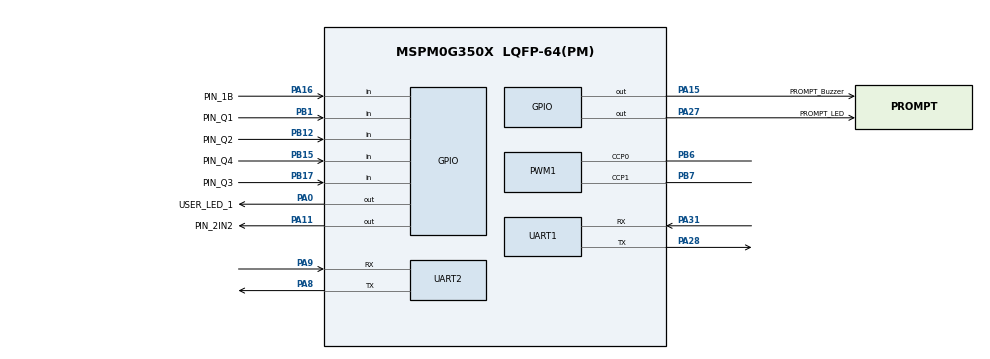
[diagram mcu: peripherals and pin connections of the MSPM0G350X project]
/**
 * @cliArgs --device "MSPM0G350X" --package "LQFP-64(PM)" --part "Default" --product "mspm0_sdk@2.01.00.03"
 * @versions {"tool":"1.20.0+3587"}
 */

/**
 * Import the modules used in this configuration.
 */
const GPIO   = scripting.addModule("/ti/driverlib/GPIO", {}, false);
const GPIO1  = GPIO.addInstance();
const GPIO2  = GPIO.addInstance();
const GPIO3  = GPIO.addInstance();
const GPIO4  = GPIO.addInstance();
const GPIO5  = GPIO.addInstance();
const GPIO6  = GPIO.addInstance();
const PWM    = scripting.addModule("/ti/driverlib/PWM", {}, false);
const PWM1   = PWM.addInstance();
const TIMER  = scripting.addModule("/ti/driverlib/TIMER", {}, false);
const TIMER1 = TIMER.addInstance();
const TIMER2 = TIMER.addInstance();
const UART   = scripting.addModule("/ti/driverlib/UART", {}, false);
const UART1  = UART.addInstance();
const UART2  = UART.addInstance();

/**
 * Write custom configuration values to the imported modules.
 */
GPIO1.$name                              = "GPIO_Flag";
GPIO1.associatedPins.create(4);
GPIO1.associatedPins[0].$name            = "USER_LED_1";
GPIO1.associatedPins[0].assignedPort     = "PORTA";
GPIO1.associatedPins[0].initialValue     = "SET";
GPIO1.associatedPins[0].assignedPin      = "0";
GPIO1.associatedPins[0].pin.$assign      = "PA0";
GPIO1.associatedPins[1].assignedPort     = "PORTA";
GPIO1.associatedPins[1].assignedPin      = "15";
GPIO1.associatedPins[1].initialValue     = "SET";
GPIO1.associatedPins[1].$name            = "PROMPT_Buzzer";
GPIO1.associatedPins[1].internalResistor = "PULL_UP";
GPIO1.associatedPins[1].pin.$assign      = "PA15";
GPIO1.associatedPins[2].$name            = "PROMPT_LED";
GPIO1.associatedPins[2].assignedPort     = "PORTA";
GPIO1.associatedPins[2].assignedPin      = "27";
GPIO1.associatedPins[2].internalResistor = "PULL_DOWN";
GPIO1.associatedPins[2].pin.$assign      = "PA27";
GPIO1.associatedPins[3].direction        = "INPUT";
GPIO1.associatedPins[3].$name            = "PIN_ResetYaw";
GPIO1.associatedPins[3].internalResistor = "PULL_UP";
GPIO1.associatedPins[3].assignedPort     = "PORTB";
GPIO1.associatedPins[3].assignedPin      = "21";

const Board           = scripting.addModule("/ti/driverlib/Board", {}, false);
Board.configureUnused = true;

GPIO2.$name                          = "GPIO_OLED";
GPIO2.associatedPins.create(2);
GPIO2.associatedPins[0].$name        = "PIN_SCL";
GPIO2.associatedPins[0].assignedPort = "PORTA";
GPIO2.associatedPins[0].assignedPin  = "13";
GPIO2.associatedPins[1].$name        = "PIN_SDA";
GPIO2.associatedPins[1].assignedPin  = "12";
GPIO2.associatedPins[1].assignedPort = "PORTA";

GPIO3.$name                          = "GPIO_Motor";
GPIO3.associatedPins.create(4);
GPIO3.associatedPins[0].$name        = "PIN_1IN1";
GPIO3.associatedPins[0].assignedPort = "PORTB";
GPIO3.associatedPins[0].assignedPin  = "8";
GPIO3.associatedPins[1].$name        = "PIN_1IN2";
GPIO3.associatedPins[1].assignedPort = "PORTB";
GPIO3.associatedPins[1].assignedPin  = "13";
GPIO3.associatedPins[2].$name        = "PIN_2IN1";
GPIO3.associatedPins[2].assignedPort = "PORTB";
GPIO3.associatedPins[2].assignedPin  = "0";
GPIO3.associatedPins[3].$name        = "PIN_2IN2";
GPIO3.associatedPins[3].pin.$assign  = "PA11";

GPIO4.$name                          = "GPIO_Encoder";
GPIO4.associatedPins.create(2);
GPIO4.associatedPins[0].$name        = "PIN_1A";
GPIO4.associatedPins[0].direction    = "INPUT";
GPIO4.associatedPins[0].interruptEn  = true;
GPIO4.associatedPins[0].polarity     = "RISE";
GPIO4.associatedPins[0].assignedPort = "PORTA";
GPIO4.associatedPins[0].assignedPin  = "17";
GPIO4.associatedPins[1].direction    = "INPUT";
GPIO4.associatedPins[1].interruptEn  = true;
GPIO4.associatedPins[1].polarity     = "RISE";
GPIO4.associatedPins[1].$name        = "PIN_1B";
GPIO4.associatedPins[1].pin.$assign  = "PA16";

GPIO5.$name                          = "GPIO_SensorTracking";
GPIO5.associatedPins.create(7);
GPIO5.associatedPins[0].$name        = "PIN_1";
GPIO5.associatedPins[0].assignedPort = "PORTA";
GPIO5.associatedPins[0].direction    = "INPUT";
GPIO5.associatedPins[0].assignedPin  = "25";
GPIO5.associatedPins[1].$name        = "PIN_2";
GPIO5.associatedPins[1].direction    = "INPUT";
GPIO5.associatedPins[1].assignedPin  = "24";
GPIO5.associatedPins[1].assignedPort = "PORTB";
GPIO5.associatedPins[2].$name        = "PIN_3";
GPIO5.associatedPins[2].assignedPort = "PORTB";
GPIO5.associatedPins[2].direction    = "INPUT";
GPIO5.associatedPins[2].assignedPin  = "9";
GPIO5.associatedPins[3].$name        = "PIN_4";
GPIO5.associatedPins[3].assignedPort = "PORTB";
GPIO5.associatedPins[3].assignedPin  = "19";
GPIO5.associatedPins[3].direction    = "INPUT";
GPIO5.associatedPins[4].$name        = "PIN_5";
GPIO5.associatedPins[4].assignedPort = "PORTA";
GPIO5.associatedPins[4].assignedPin  = "22";
GPIO5.associatedPins[4].direction    = "INPUT";
GPIO5.associatedPins[5].$name        = "PIN_6";
GPIO5.associatedPins[5].assignedPort = "PORTB";
GPIO5.associatedPins[5].assignedPin  = "18";
GPIO5.associatedPins[5].direction    = "INPUT";
GPIO5.associatedPins[6].$name        = "PIN_7";
GPIO5.associatedPins[6].assignedPort = "PORTA";
GPIO5.associatedPins[6].assignedPin  = "18";
GPIO5.associatedPins[6].direction    = "INPUT";

GPIO6.$name                              = "GPIO_Questions";
GPIO6.associatedPins.create(4);
GPIO6.associatedPins[0].$name            = "PIN_Q1";
GPIO6.associatedPins[0].direction        = "INPUT";
GPIO6.associatedPins[0].internalResistor = "PULL_UP";
GPIO6.associatedPins[0].polarity         = "RISE";
GPIO6.associatedPins[0].inputFilter      = "8_CYCLES";
GPIO6.associatedPins[0].interruptEn      = true;
GPIO6.associatedPins[0].pin.$assign      = "PB1";
GPIO6.associatedPins[1].$name            = "PIN_Q2";
GPIO6.associatedPins[1].direction        = "INPUT";
GPIO6.associatedPins[1].internalResistor = "PULL_UP";
GPIO6.associatedPins[1].polarity         = "RISE";
GPIO6.associatedPins[1].inputFilter      = "8_CYCLES";
GPIO6.associatedPins[1].interruptEn      = true;
GPIO6.associatedPins[1].pin.$assign      = "PB12";
GPIO6.associatedPins[2].$name            = "PIN_Q3";
GPIO6.associatedPins[2].direction        = "INPUT";
GPIO6.associatedPins[2].internalResistor = "PULL_UP";
GPIO6.associatedPins[2].polarity         = "RISE";
GPIO6.associatedPins[2].inputFilter      = "8_CYCLES";
GPIO6.associatedPins[2].interruptEn      = true;
GPIO6.associatedPins[2].pin.$assign      = "PB17";
GPIO6.associatedPins[3].$name            = "PIN_Q4";
GPIO6.associatedPins[3].direction        = "INPUT";
GPIO6.associatedPins[3].internalResistor = "PULL_UP";
GPIO6.associatedPins[3].polarity         = "RISE";
GPIO6.associatedPins[3].inputFilter      = "8_CYCLES";
GPIO6.associatedPins[3].interruptEn      = true;
GPIO6.associatedPins[3].pin.$assign      = "PB15";

PWM1.$name                              = "PWM_Motor";
PWM1.clockDivider                       = 2;
PWM1.clockPrescale                      = 16;
PWM1.pwmMode                            = "EDGE_ALIGN_UP";
PWM1.peripheral.$assign                 = "TIMG6";
PWM1.peripheral.ccp0Pin.$assign         = "PB6";
PWM1.peripheral.ccp1Pin.$assign         = "PB7";
PWM1.PWM_CHANNEL_0.$name                = "ti_driverlib_pwm_PWMTimerCC0";
PWM1.PWM_CHANNEL_0.dutyCycle            = 75;
PWM1.PWM_CHANNEL_1.$name                = "ti_driverlib_pwm_PWMTimerCC1";
PWM1.PWM_CHANNEL_1.dutyCycle            = 75;
PWM1.ccp0PinConfig.direction            = scripting.forceWrite("OUTPUT");
PWM1.ccp0PinConfig.hideOutputInversion  = scripting.forceWrite(false);
PWM1.ccp0PinConfig.onlyInternalResistor = scripting.forceWrite(false);
PWM1.ccp0PinConfig.passedPeripheralType = scripting.forceWrite("Digital");
PWM1.ccp0PinConfig.$name                = "ti_driverlib_gpio_GPIOPinGeneric4";
PWM1.ccp1PinConfig.direction            = scripting.forceWrite("OUTPUT");
PWM1.ccp1PinConfig.hideOutputInversion  = scripting.forceWrite(false);
PWM1.ccp1PinConfig.onlyInternalResistor = scripting.forceWrite(false);
PWM1.ccp1PinConfig.passedPeripheralType = scripting.forceWrite("Digital");
PWM1.ccp1PinConfig.$name                = "ti_driverlib_gpio_GPIOPinGeneric5";

const SYSCTL                 = scripting.addModule("/ti/driverlib/SYSCTL", {}, false);
SYSCTL.powerPolicy           = "STANDBY0";
SYSCTL.forceDefaultClkConfig = true;
SYSCTL.clockTreeEn           = true;

TIMER1.timerClkDiv        = 4;
TIMER1.timerClkPrescale   = 128;
TIMER1.timerMode          = "PERIODIC";
TIMER1.interrupts         = ["ZERO"];
TIMER1.$name              = "TIMER_computePID";
TIMER1.timerPeriod        = "200 ms";
TIMER1.peripheral.$assign = "TIMA0";

TIMER2.timerClkDiv        = 4;
TIMER2.interrupts         = ["ZERO"];
TIMER2.timerMode          = "PERIODIC";
TIMER2.$name              = "TIMER_Debug";
TIMER2.timerClkPrescale   = 128;
TIMER2.timerPeriod        = "600 ms";
TIMER2.peripheral.$assign = "TIMA1";

UART1.$name                    = "UART_0";
UART1.rxFifoThreshold          = "DL_UART_RX_FIFO_LEVEL_ONE_ENTRY";
UART1.enableDMARX              = false;
UART1.enableDMATX              = false;
UART1.enabledInterrupts        = ["RX"];
UART1.targetBaudRate           = 115200;
UART1.peripheral.$assign       = "UART0";
UART1.peripheral.rxPin.$assign = "PA31";
UART1.peripheral.txPin.$assign = "PA28";
UART1.txPinConfig.$name        = "ti_driverlib_gpio_GPIOPinGeneric0";
UART1.rxPinConfig.$name        = "ti_driverlib_gpio_GPIOPinGeneric1";

UART2.$name                            = "UART_JY60";
UART2.enabledInterrupts                = ["RX"];
UART2.peripheral.$assign               = "UART1";
UART2.peripheral.rxPin.$assign         = "PA9";
UART2.peripheral.txPin.$assign         = "PA8";
UART2.txPinConfig.direction            = scripting.forceWrite("OUTPUT");
UART2.txPinConfig.hideOutputInversion  = scripting.forceWrite(false);
UART2.txPinConfig.onlyInternalResistor = scripting.forceWrite(false);
UART2.txPinConfig.passedPeripheralType = scripting.forceWrite("Digital");
UART2.txPinConfig.$name                = "ti_driverlib_gpio_GPIOPinGeneric6";
UART2.rxPinConfig.hideOutputInversion  = scripting.forceWrite(false);
UART2.rxPinConfig.onlyInternalResistor = scripting.forceWrite(false);
UART2.rxPinConfig.passedPeripheralType = scripting.forceWrite("Digital");
UART2.rxPinConfig.$name                = "ti_driverlib_gpio_GPIOPinGeneric7";

/**
 * Pinmux solution for unlocked pins/peripherals. This ensures that minor changes to the automatic solver in a future
 * version of the tool will not impact the pinmux you originally saw.  These lines can be completely deleted in order to
 * re-solve from scratch.
 */
GPIO1.associatedPins[3].pin.$suggestSolution = "PB21";
Board.peripheral.$suggestSolution            = "DEBUGSS";
Board.peripheral.swclkPin.$suggestSolution   = "PA20";
Board.peripheral.swdioPin.$suggestSolution   = "PA19";
GPIO2.associatedPins[0].pin.$suggestSolution = "PA13";
GPIO2.associatedPins[1].pin.$suggestSolution = "PA12";
GPIO3.associatedPins[0].pin.$suggestSolution = "PB8";
GPIO3.associatedPins[1].pin.$suggestSolution = "PB13";
GPIO3.associatedPins[2].pin.$suggestSolution = "PB0";
GPIO4.associatedPins[0].pin.$suggestSolution = "PA17";
GPIO5.associatedPins[0].pin.$suggestSolution = "PA25";
GPIO5.associatedPins[1].pin.$suggestSolution = "PB24";
GPIO5.associatedPins[2].pin.$suggestSolution = "PB9";
GPIO5.associatedPins[3].pin.$suggestSolution = "PB19";
GPIO5.associatedPins[4].pin.$suggestSolution = "PA22";
GPIO5.associatedPins[5].pin.$suggestSolution = "PB18";
GPIO5.associatedPins[6].pin.$suggestSolution = "PA18";
